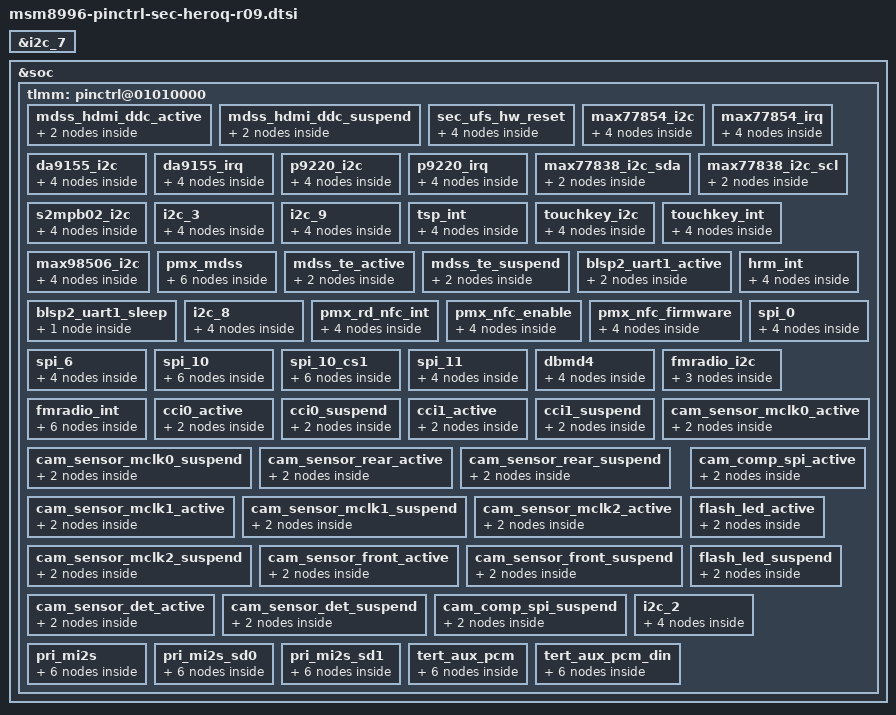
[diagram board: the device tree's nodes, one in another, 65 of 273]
/* Copyright (c) 2014-2015, The Linux Foundation. All rights reserved.
 *
 * This program is free software; you can redistribute it and/or modify
 * it under the terms of the GNU General Public License version 2 and
 * only version 2 as published by the Free Software Foundation.
 *
 * This program is distributed in the hope that it will be useful,
 * but WITHOUT ANY WARRANTY; without even the implied warranty of
 * MERCHANTABILITY or FITNESS FOR A PARTICULAR PURPOSE.  See the
 * GNU General Public License for more details.
 */

#include "msm8996-pinctrl-sec-heroq-common.dtsi"

&i2c_7 {
	/delete-node/ silabs4705@11;
};

&soc {
	tlmm: pinctrl@01010000 {
		/delete-node/ pmx_fm_int;
		/delete-node/ mdss_hdmi_ddc_active;
		/delete-node/ mdss_hdmi_ddc_suspend;
		mdss_hdmi_ddc_active: mdss_hdmi_ddc_active {
			mux {
				pins = "gpio93", "gpio94";
				function = "hdmi_ddc";
			};

			config {
				pins = "gpio93", "gpio94";
				drive-strength = <2>;
				bias-pull-up;
			};
		};

		mdss_hdmi_ddc_suspend: mdss_hdmi_ddc_suspend {
			mux {
				pins = "gpio93", "gpio94";
				function = "hdmi_ddc";
			};

			config {
				pins = "gpio93", "gpio94";
				drive-strength = <2>;
				bias-pull-down;
			};
		};

		sec_ufs_hw_reset {
			ufs_power_on: ufs_power_on {
				sec_ufs_hw_reset {
					pins = "gpio89";
					bias-disable;
					output-low;
				};
			};
			ufs_power_off: ufs_power_off {
				sec_ufs_hw_reset {
					pins = "gpio89";
					bias-disable;
					output-high;
				};
			};
		};

		max77854_i2c {
			max77854_i2c_active: max77854_i2c_active {
				max77854_i2c {
					pins = "gpio33", "gpio32";
					drive-strength = <2>;
					function = "NA";
					bias-disable;
				};
			};
			max77854_i2c_suspend: max77854_i2c_suspend {
				max77854_i2c {
					pins = "gpio33", "gpio32";
					drive-strength = <2>;
					function = "NA";
					bias-disable;
				};
			};
		};

		max77854_irq {
			max77854_irq_active: max77854_irq_active {
				max77854_irq {
					pins = "gpio38";
					drive-strength = <2>;
					function = "NA";
					bias-disable;
				};
			};
			max77854_irq_suspend: max77854_irq_suspend {
				max77854_irq {
					pins = "gpio38";
					drive-strength = <2>;
					function = "NA";
					bias-disable;
				};
			};
		};

		da9155_i2c {
			da9155_i2c_active: da9155_i2c_active {
				da9155_i2c {
					pins = "gpio33", "gpio32";
					drive-strength = <2>;
					bias-disable;
				};
			};
			da9155_i2c_suspend:da9155_i2c_suspend {
				da9155_i2c {
					pins = "gpio33", "gpio32";
					drive-strength = <2>;
					bias-disable;
				};
			};
		};

		da9155_irq {
			da9155_irq_active: da9155_irq_active {
				da9155_irq {
					pins = "gpio34";
					drive-strength = <2>;
					bias-disable;
				};
			};
			da9155_irq_suspend: da9155_irq_suspend {
				da9155_irq {
					pins = "gpio34";
					drive-strength = <2>;
					bias-disable;
				};
			};
		};

		p9220_i2c {
			p9220_i2c_active: p9220_i2c_active {
				p9220_i2c {
					pins = "gpio97", "gpio98";
					drive-strength = <2>;
					bias-disable;
				};
			};
			p9220_i2c_suspend: p9220_i2c_suspend {
				p9220_i2c {
					pins = "gpio97", "gpio98";
					drive-strength = <2>;
					bias-disable;
				};
			};
		};

		p9220_irq {
			p9220_irq_active: p9220_irq_active {
				p9220_irq {
					pins = "gpio127";
					drive-strength = <2>;
					bias-disable;
				};
			};
			p9220_irq_suspend: p9220_irq_suspend {
				p9220_irq {
					pins = "gpio127";
					drive-strength = <2>;
					bias-disable;
				};
			};
		};

		max77838_i2c_sda {
			max77838_i2c_sda_default: max77838_i2c_sda_default {
				max77838_i2c_sda {
					pins = "gpio16";
					drive-strength = <2>;
					bias-disable;
				};
			};
		};
		max77838_i2c_sda {
			max77838_i2c_sda_default: max77838_i2c_sda_default {
				max77838_i2c_sda {
					pins = "gpio16";
					drive-strength = <2>;
					bias-disable;
				};
			};
		};

		max77838_i2c_scl {
			max77838_i2c_scl_default: max77838_i2c_scl_default {
				max77838_i2c_scl {
					pins = "gpio29";
					drive-strength = <2>;
					bias-disable;
				};
			};
		};

		s2mpb02_i2c {
			s2mpb02_i2c_active: s2mpb02_i2c_active {
				s2mpb02_i2c {
					pins = "gpio87", "gpio88";
					drive-strength = <2>;
					bias-disable;
					function = "blsp_i2c12";
				};
			};
			s2mpb02_i2c_suspend: s2mpb02_i2c_suspend {
				s2mpb02_i2c {
					pins = "gpio87", "gpio88";
					drive-strength = <2>;
					bias-disable;
					function = "blsp_i2c12";
				};
			};
		};

		i2c_3 {
			i2c_3_active: i2c_3_active {
				i2c_3 {
					pins = "gpio47", "gpio48";
					function = "blsp_i2c3";
					drive-strength = <2>;
					bias-disable;
				};
			};

			i2c_3_sleep: i2c_3_sleep {
				i2c_3 {
					pins = "gpio47", "gpio48";
					function = "blsp_i2c3";
					drive-strength = <2>;
					bias-pull-up;
				};
			};
		};

		i2c_9 {
			i2c_9_active: i2c_9_active {
				i2c_9 {
					pins = "gpio51", "gpio52";
					function = "blsp_i2c9";
					drive-strength = <2>;
					bias-disable;
				};
			};

			i2c_9_sleep: i2c_9_sleep {
				i2c_9 {
					pins = "gpio51", "gpio52";
					function = "blsp_i2c9";
					drive-strength = <2>;
					bias-pull-up;
				};
			};
		};

		tsp_int {
			tsp_int_active: tsp_int_active {
				tsp_int_active {
					pins = "gpio123";
					drive-strength = <2>;
					bias-disable;
				};
			};
			tsp_int_suspend: tsp_int_suspend {
				tsp_int_suspend {
					pins = "gpio123";
					drive-strength = <2>;
					bias-disable;
				};
			};
		};

		touchkey_i2c {
			touchkey_i2c_active: touchkey_i2c_active {
				touchkey_i2c_active {
					pins = "gpio21", "gpio22";
					drive-strength = <2>;
					bias-disable;
				};
			};
			touchkey_i2c_suspend: touchkey_i2c_suspend {
				touchkey_i2c_suspend {
					pins = "gpio21", "gpio22";
					drive-strength = <2>;
					bias-disable;
				};
			};
		};

		touchkey_int {
			touchkey_int_active: touchkey_int_active {
				touchkey_int_active {
					pins = "gpio64";
					drive-strength = <2>;
					bias-pull-up;
				};
			};
			touchkey_int_suspend: touchkey_int_suspend {
				touchkey_int_suspend {
					pins = "gpio64";
					drive-strength = <2>;
					bias-disable;
				};
			};
		};

		max98506_i2c {
			max98506_i2c_default: max98506_i2c_default {
				max98506_i2c {
					pins = "gpio41", "gpio80";
					function = "gpio";
					drive-strength = <2>;
					bias-disable;
				};
			};
			max98506_i2c_sleep: max98506_i2c_sleep {
				max98506_i2c {
					pins = "gpio41", "gpio80";
					function = "gpio";
					drive-strength = <2>;
					bias-disable;
				};
			};
		};

		pmx_mdss: pmx_mdss {
			mdss_dsi_active: mdss_dsi_active {
				mux {
					pins = "gpio143";
					function = "gpio";
				};

				config {
					pins = "gpio143";
					drive-strength = <8>; /* 8 mA */
					bias-disable = <0>; /* no pull */
					output-high;
				};
			};
			mdss_dsi_suspend: mdss_dsi_suspend {
				mux {
					pins = "gpio143";
					function = "gpio";
				};

				config {
					pins = "gpio143";
					drive-strength = <2>; /* 2 mA */
					bias-pull-down; /* pull down */
				};
			};
		};

		mdss_te_active: mdss_te_active {
			mux {
				pins = "gpio10";
				function = "mdp_vsync";
			};
			config {
				pins = "gpio10";
				drive-strength = <2>; /* 8 mA */
				bias-pull-down; /* pull down*/
			};
		};


		mdss_te_suspend: mdss_te_suspend {
			mux {
				pins = "gpio10";
				function = "mdp_vsync";
			};
			config {
				pins = "gpio10";
				drive-strength = <2>; /* 2 mA */
				bias-pull-down; /* pull down */
			};
		};

		blsp2_uart1_active: blsp2_uart1_active {
			mux {
				pins = "gpio53", "gpio54", "gpio55", "gpio56";
				function = "blsp_uart7";
			};

			config {
				pins = "gpio53", "gpio54", "gpio55", "gpio56";
				drive-strength = <2>;
				bias-disable;
			};
		};

		blsp2_uart1_sleep: blsp2_uart1_sleep {
			config {
				pins = "gpio53", "gpio54", "gpio55", "gpio56";
				drive-strength = <2>;
				bias-pull-up;
			};
		};

		hrm_int {
			hrm_int_active: hrm_int_active {
				hrm_int_active {
					pins = "gpio119";
					drive-strength = <2>;
					bias-pull-up;
				};
			};
			hrm_int_suspend: hrm_int_suspend {
				hrm_int_suspend {
					pins = "gpio119";
					drive-strength = <2>;
					bias-disable;
				};
			};
		};

		i2c_8 {
			i2c_8_active: i2c_8_active {
				i2c_8 {
					pins = "gpio6", "gpio7";
					function = "blsp_i2c8";
					drive-strength = <2>;
					bias-disable;
				};
			};

			i2c_8_sleep: i2c_8_sleep {
				i2c_8 {
					pins = "gpio6", "gpio7";
					function = "blsp_i2c8";
					drive-strength = <2>;
					bias-pull-up;
				};
			};
		};
		pmx_rd_nfc_int{
			nfc_int_active: nfc_int_active {
				pmx_rd_nfc_int {
					pins = "gpio126";
					drive-strength = <6>;
					bias-pull-up;
				};
			};

			nfc_int_suspend: nfc_int_suspend {
				pmx_rd_nfc_int {
					pins = "gpio126";
			    	        drive-strength = <6>;
			    	        bias-pull-up;
				};
			};
        };

		pmx_nfc_enable{
			nfc_enable_active: nfc_enable_active {
				pmx_nfc_enable{
					pins = "gpio62";
					drive-strength = <2>;
					bias-pull-down; /* PULL DOWN */
				};
			};

			nfc_enable_suspend: nfc_enable_suspend {
				pmx_nfc_enable{
					pins = "gpio62";
					drive-strength = <2>;
					bias-pull-down; /* PULL DOWN */
				};
			};
		};

        pmx_nfc_firmware{
			nfc_firmware_active: nfc_firmware_active {
				pmx_nfc_firmware{
					pins = "gpio63";
					drive-strength = <2>;
					bias-pull-down; /* PULL DOWN */
				};
			};

			nfc_firmware_suspend: nfc_firmware_suspend {
				pmx_nfc_firmware{
					pins = "gpio63";
					drive-strength = <2>;
					bias-pull-down; /* PULL DOWN */
				};
			};
		};

		spi_0 {
			spi_0_active: spi_0_active {
				spi_0 {
					pins = "gpio0", "gpio1", "gpio2", "gpio3";
					function = "blsp_spi1";
					drive-strength = <6>;
					bias-disable;
				};
			};

			spi_0_sleep: spi_0_sleep {
				spi_0 {
					pins = "gpio0", "gpio1", "gpio2", "gpio3";
					function = "blsp_spi1";
					drive-strength = <6>;
					bias-disable;
				};
			};
		};

		spi_6 {
			spi_6_active: spi_6_active {
				spi_6 {
					pins = "gpio25", "gpio26", "gpio27", "gpio28";
					function = "blsp_spi6";
					drive-strength = <6>;
					bias-disable;
				};
			};

			spi_6_sleep: spi_6_sleep {
				spi_6 {
					pins = "gpio25", "gpio26", "gpio27", "gpio28";
					function = "blsp_spi6";
					drive-strength = <6>;
					bias-pull-down;
				};
			};
		};

		spi_10 {
			/* MOSI, MISO, CLK */
			spi_10_active: spi_10_active {
				mux {
					pins = "gpio8", "gpio9", "gpio11";
					function = "blsp_spi10";
				};

				config {
					pins = "gpio8", "gpio9", "gpio11";
					drive-strength = <6>;
					bias-disable;
				};
			};

			spi_10_sleep: spi_10_sleep {
				mux {
					pins = "gpio8", "gpio9", "gpio11";
					function = "blsp_spi10";
				};

				config {
					pins = "gpio8", "gpio9", "gpio11";
					drive-strength = <6>;
					bias-pull-down;
				};
			};
		};

		spi_10_cs1 {
			/* CS1, CS2 */
			spi_10_cs1_active: spi_10_cs1_active {
				mux {
					pins = "gpio49", "gpio50";
					function = "blsp10_spi";
				};

				config {
					pins = "gpio49", "gpio50";
					drive-strength = <6>;
					bias-disable;
				};
			};

			spi_10_cs1_sleep: spi_10_cs1_sleep {
				mux {
					pins = "gpio49", "gpio50";
					function = "blsp10_spi";
				};

				config {
					pins = "gpio49", "gpio50";
					drive-strength = <6>;
					bias-pull-down;
				};
			};
		};

		spi_11 {
			spi_11_active: spi_11_active {
				spi_11 {
					pins = "gpio58", "gpio59", "gpio60", "gpio61";
					function = "blsp_spi11";
					drive-strength = <6>;
					bias-disable;
				};
			};

			spi_11_sleep: spi_11_sleep {
				spi_11 {
					pins = "gpio58", "gpio59", "gpio60", "gpio61";
					function = "blsp_spi11";
					drive-strength = <6>;
					bias-disable;
				};
			};
		};

		dbmd4 {
			dbmdx_active: dbmdx_active {
				dbmd4 {
					pins = "gpio42";
					drive-strength = <2>;
					bias-pull-down;
				};
			};

			dbmdx_sleep: dbmdx_sleep {
				dbmd4 {
					pins = "gpio42";
					drive-strength = <2>;
					bias-pull-down;
				};
			};
		};

		fmradio_i2c {
			fmradio_i2c_default: fmradio_i2c_default {
				mux {
					pins = "gpio45", "gpio23";
					function = "gpio";
				};
				config {
					pins = "gpio45", "gpio23";
					drive-strength = <2>; /* 2 MA */
					bias-disable; /* No PULL */
				};
			};
		};

		fmradio_int {
			fmradio_int_active: fmradio_int_active {
				mux {
					pins = "gpio132";
					function = "gpio";
				};
				config {
					pins = "gpio132";
					drive-strength = <2>; /* 2 MA */
					bias-pull-down; /* PULL DOWN */
				};
			};

			fmradio_int_suspend: fmradio_int_suspend {
				mux {
					pins = "gpio132";
					function = "gpio";
				};
				config {
					pins = "gpio132";
					drive-strength = <2>; /* 2 MA */
					bias-pull-down; /* PULL DOWN */
				};
			};
		};

		/* pin-ctrl for camera sensor */
		cci0_active: cci0_active {
			mux {
				/* CLK, DATA */
				pins = "gpio17","gpio18"; // Only 2
				function = "cci_i2c";
			};
			config {
				pins = "gpio17","gpio18";
				bias-disable; /* No PULL */
				drive-strength = <2>; /* 2 MA */
			};
		};

		cci0_suspend: cci0_suspend {
			mux {
				/* CLK, DATA */
				pins = "gpio17","gpio18";
				function = "gpio";
			};
			config {
				pins = "gpio17","gpio18";
				bias-pull-down;
				drive-strength = <2>; /* 2 MA */
			};
		};

		cci1_active: cci1_active {
			mux {
				/* CLK, DATA */
				pins = "gpio19","gpio20";
				function = "cci_i2c";
			};
			config {
				pins = "gpio19","gpio20";
				bias-disable; /* No PULL */
				drive-strength = <2>; /* 2 MA */
			};
		};

		cci1_suspend: cci1_suspend {
			mux {
				/* CLK, DATA */
				pins = "gpio19","gpio20";
				function = "gpio";
			};
			config {
				pins = "gpio19","gpio20";
				bias-pull-down;
				drive-strength = <2>; /* 2 MA */
			};
		};

		cam_sensor_mclk0_active: cam_sensor_mclk0_active {
			/* MCLK0 */
			mux {
				/* CLK, DATA */
				pins = "gpio13";
				function = "cam_mclk";
			};
			config {
				pins = "gpio13";
				bias-disable; /* No PULL */
				drive-strength = <2>; /* 2 MA */
			};
		};

		cam_sensor_mclk0_suspend: cam_sensor_mclk0_suspend {
			/* MCLK0 */
			mux {
				/* CLK, DATA */
				pins = "gpio13";
				function = "cam_mclk";
			};
			config {
				pins = "gpio13";
				bias-pull-down; /* PULL DOWN */
				drive-strength = <2>; /* 2 MA */
			};
		};

		cam_sensor_rear_active: cam_sensor_rear_active {
			/* RESET */
			mux {
				pins = "gpio30";
				function = "gpio";
			};
			config {
				pins = "gpio30";
				bias-disable; /* No PULL */
				drive-strength = <2>; /* 2 MA */
			};
		};

		cam_sensor_rear_suspend: cam_sensor_rear_suspend{
			/* RESET */
			mux {
				pins = "gpio30";
				function = "gpio";
			};
			config {
				pins = "gpio30";
				bias-pull-down;
				drive-strength = <2>; /* 2 MA */
			};
		};

		cam_sensor_mclk1_active: cam_sensor_mclk1_active{
			/* MCLK1 */
			mux {
				/* CLK, DATA */
				pins = "gpio14";
				function = "cam_mclk";
			};
			config {
				pins = "gpio14";
				bias-disable; /* No PULL */
				drive-strength = <2>; /* 2 MA */
			};
		};

		cam_sensor_mclk1_suspend: cam_sensor_mclk1_suspend {
			/* MCLK1 */
			mux {
				/* CLK, DATA */
				pins = "gpio14";
				function = "cam_mclk";
			};
			config {
				pins = "gpio14";
				bias-pull-down; /* PULL DOWN */
				drive-strength = <2>; /* 2 MA */
			};
		};

		cam_sensor_mclk2_active: cam_sensor_mclk2_active {
			/* MCLK1 */
			mux {
				/* CLK, DATA */
				pins = "gpio15";
				function = "cam_mclk";
			};
			config {
				pins = "gpio15";
				bias-disable; /* No PULL */
				drive-strength = <2>; /* 2 MA */
			};
		};

		cam_sensor_mclk2_suspend: cam_sensor_mclk2_suspend{
			/* MCLK1 */
			mux {
				/* CLK, DATA */
				pins = "gpio15";
				function = "cam_mclk";
			};
			config {
				pins = "gpio15";
				bias-pull-down; /* PULL DOWN */
				drive-strength = <2>; /* 2 MA */
			};
		};

		cam_sensor_front_active: cam_sensor_front_active{
			/* RESET */
			mux {
				pins = "gpio39", "gpio40";
				function = "gpio";
			};

			config {
				pins = "gpio39", "gpio40";
				bias-disable; /* No PULL */
				drive-strength = <2>; /* 2 MA */
			};
		};

		cam_sensor_front_suspend: cam_sensor_front_suspend{
			/* RESET */
			mux {
				pins = "gpio39", "gpio40";
				function = "gpio";
			};

			config {
				pins = "gpio39", "gpio40";
				bias-pull-down;
				drive-strength = <2>; /* 2 MA */
			};
		};

		cam_sensor_det_active: cam_sensor_det_active{
			/* SENSOR_DET */
			mux {
				pins = "gpio89";
				function = "gpio";
			};

			config {
				pins = "gpio89";
				bias-disable; /* No PULL */
				drive-strength = <2>; /* 2 MA */
			};
		};

		cam_sensor_det_suspend: cam_sensor_det_suspend{
			/* SENSOR_DET */
			mux {
				pins = "gpio89";
				function = "gpio";
			};

			config {
				pins = "gpio89";
				bias-disable; /* No PULL */
				drive-strength = <2>; /* 2 MA */
			};
		};

		cam_comp_spi_active: cam_comp_spi_active {
			/* COMP_RESET, COMP_INT */
			mux {
				pins = "gpio91", "gpio92";
				function = "gpio";
			};

			config {
				pins = "gpio91", "gpio92";
				bias-pull-up;
				drive-strength = <2>; /* 2 MA */
			};
		};

		cam_comp_spi_suspend: cam_comp_spi_suspend {
			/* COMP_RESET, COMP_INT */
			mux {
				pins = "gpio91", "gpio92";
				function = "gpio";
			};

			config {
				pins = "gpio91", "gpio92";
				bias-pull-down;
				drive-strength = <2>; /* 2 MA */
			};
		};

		flash_led_active: flash_led_active {
			mux {
				pins = "gpio12","gpio96";
				function = "gpio";
			};

			config {
				pins = "gpio12","gpio96";
				bias-disable; /* No PULL */
				drive-strength = <2>; /* 2 MA */
			};
		};

		flash_led_suspend: flash_led_suspend {
			mux {
				pins = "gpio12","gpio96";
				function = "gpio";
			};

			config {
				pins = "gpio12","gpio96";
				bias-disable; /* No PULL */
				drive-strength = <2>; /* 2 MA */
				output-low;
			};
		};

		i2c_2 {
			i2c_2_active: i2c_2_active {
				i2c_2 {
					pins = "gpio43", "gpio44";
					function = "blsp_i2c2";
					drive-strength = <2>;
					bias-disable;
				};
			};

			i2c_2_sleep: i2c_2_sleep {
				i2c_2 {
					pins = "gpio43", "gpio44";
					function = "blsp_i2c2";
					drive-strength = <2>;
					bias-pull-down;
				};
			};
		};

		pri_mi2s {
			pri_mi2s_sleep: pri_mi2s_sleep {
				mux {
					pins = "gpio65", "gpio66";
					function = "pri_mi2s";
				};

				config {
					pins = "gpio65", "gpio66";
					drive-strength = <2>;   /* 2 mA */
					bias-pull-down;         /* PULL DOWN */
				};
			};
			pri_mi2s_active: pri_mi2s_active {
				mux {
					pins = "gpio65", "gpio66";
					function = "pri_mi2s";
				};

				config {
					pins = "gpio65", "gpio66";
					drive-strength = <8>;   /* 2 mA */
					bias-disable;           /* NO PULL */
					output-high;
				};
			};
		};

		pri_mi2s_sd0 {
			pri_mi2s_sd0_sleep: pri_mi2s_sd0_sleep {
				mux {
					pins = "gpio67";
					function = "pri_mi2s";
				};

				config {
					pins = "gpio67";
					drive-strength = <2>;   /* 2 mA */
					bias-pull-down;         /* PULL DOWN */
				};
			};
			pri_mi2s_sd0_active: pri_mi2s_sd0_active {
				mux {
					pins = "gpio67";
					function = "pri_mi2s";
				};

				config {
					pins = "gpio67";
					drive-strength = <8>;   /* 8 mA */
					bias-disable;           /* NO PULL */
				};
			};
		};

		pri_mi2s_sd1 {
			pri_mi2s_sd1_sleep: pri_mi2s_sd1_sleep {
				mux {
					pins = "gpio68";
					function = "pri_mi2s";
				};

				config {
					pins = "gpio68";
					drive-strength = <2>;   /* 2 mA */
					bias-pull-down;         /* PULL DOWN */
				};
			};
			pri_mi2s_sd1_active: pri_mi2s_sd1_active {
				mux {
					pins = "gpio68";
					function = "pri_mi2s";
				};

				config {
					pins = "gpio68";
					drive-strength = <8>;   /* 8 mA */
					bias-disable;           /* NO PULL */
				};
			};
		};

		tert_aux_pcm {
			tert_aux_pcm_sleep: tert_aux_pcm_sleep {
				mux {
					pins = "gpio75", "gpio76", "gpio77";
					function = "ter_mi2s";
				};

				config {
					pins = "gpio75", "gpio76", "gpio77";
					drive-strength = <2>;   /* 2 mA */
					bias-pull-down;         /* PULL DOWN */
				};
			};
			tert_aux_pcm_active: tert_aux_pcm_active {
				mux {
					pins = "gpio75", "gpio76", "gpio77";
					function = "ter_mi2s";
				};

				config {
					pins = "gpio75", "gpio76", "gpio77";
					drive-strength = <8>;   /* 8 mA */
					bias-disable;           /* NO PULL */
					output-high;
				};
			};
		};

		tert_aux_pcm_din {
			tert_aux_pcm_din_sleep: tert_aux_pcm_din_sleep {
				mux {
					pins = "gpio78";
					function = "ter_mi2s";
				};

				config {
					pins = "gpio78";
					drive-strength = <2>;   /* 2 mA */
					bias-pull-down;         /* PULL DOWN */
				};
			};
			tert_aux_pcm_din_active: tert_aux_pcm_din_active {
				mux {
					pins = "gpio78";
					function = "ter_mi2s";
				};

				config {
					pins = "gpio78";
					drive-strength = <8>;   /* 8 mA */
					bias-disable;           /* NO PULL */
				};
			};
		};
	};
};
